# USB1_VBP2AHB_WRAP_CONTROLLER_VBP_USB3_CORE_GBL register map
Vendor: Texas Instruments
Registers are 32-bit, read-only, reset 0x0 unless marked. A register's access mark holds for its fields unless they carry their own. Offsets are as the file gives them; [hi:lo] are bit positions; lines under a group give offsets from that group; {n}, {i} and the like mark numbered series; <NAME> marks a mode.

## USB1_VBP2AHB_WRAP_CONTROLLER_VBP_USB3_CORE_GBL (part 3 of 3)
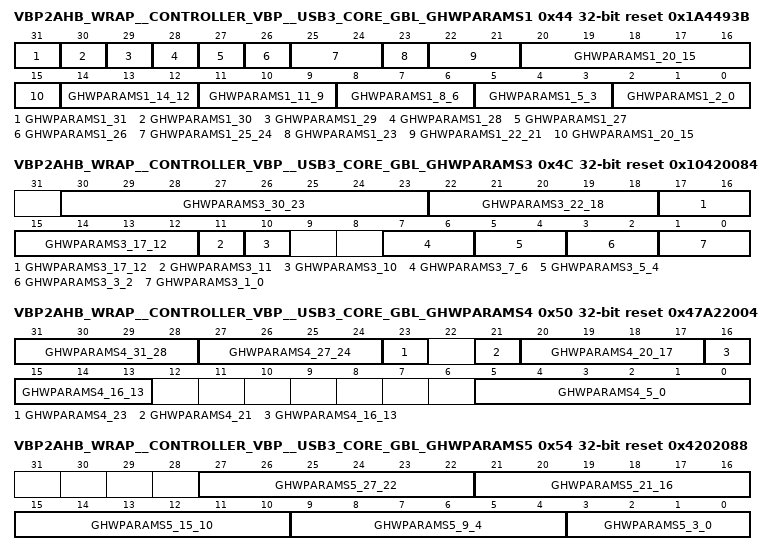
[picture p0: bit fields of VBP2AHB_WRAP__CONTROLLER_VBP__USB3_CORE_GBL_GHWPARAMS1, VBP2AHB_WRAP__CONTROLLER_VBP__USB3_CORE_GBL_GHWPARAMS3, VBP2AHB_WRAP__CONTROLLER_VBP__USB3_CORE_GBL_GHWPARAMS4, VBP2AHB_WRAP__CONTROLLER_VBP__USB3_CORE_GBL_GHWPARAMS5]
0x44 VBP2AHB_WRAP__CONTROLLER_VBP__USB3_CORE_GBL_GHWPARAMS1 reset 0x1A4493B — Global Hardware Parameters Register 1 This register contains the hardware configuration options that you can select in the coreConsultant GUI. For a description of each parameter, refer to the Parameter Descriptions chapter in the Databook. This information is also available in coreConsultant by right-clicking the parameter label and selecting What's This or by clicking the Help tab. Note: Some of the global hardware parameters are not currently modifiable in coreConsultant. These settings are in the <workspace>/src/DWC_usb3_params.v file. you must not change them.
  [31] GHWPARAMS1_31 — DWC_USB3_EN_DBC
  [30] GHWPARAMS1_30 — DWC_USB3_RM_OPT_FEATURES
  [29] GHWPARAMS1_29 — Reserved1
  [28] GHWPARAMS1_28 — DWC_USB3_RAM_BUS_CLKS_SYNC
  [27] GHWPARAMS1_27 — DWC_USB3_MAC_RAM_CLKS_SYNC
  [26] GHWPARAMS1_26 — DWC_USB3_MAC_PHY_CLKS_SYNC
  [25:24] GHWPARAMS1_25_24 — DWC_USB3_EN_PWROPT
  [23] GHWPARAMS1_23 — DWC_USB3_SPRAM_TYP
  [22:21] GHWPARAMS1_22_21 — DWC_USB3_NUM_RAMS
  [20:15] GHWPARAMS1_20_15 — DWC_USB3_DEVICE_NUM_INT For details on DWC_USB3_DEVICE_NUM_INT, refer to <workspace>/src/DWC_usb3_params.v file.
  [14:12] GHWPARAMS1_14_12 — DWC_USB3_ASPACEWIDTH
  [11:9] GHWPARAMS1_11_9 — DWC_USB3_REQINFOWIDTH
  [8:6] GHWPARAMS1_8_6 — DWC_USB3_DATAINFOWIDTH
  [5:3] GHWPARAMS1_5_3 — DWC_USB3_BURSTWIDTH-1
  [2:0] GHWPARAMS1_2_0 — DWC_USB3_IDWIDTH-1
0x48 VBP2AHB_WRAP__CONTROLLER_VBP__USB3_CORE_GBL_GHWPARAMS2 — Global Hardware Parameters Register 2 This register contains the hardware configuration options that you can select in the coreConsultant GUI. For a description of each parameter, refer to the Parameter Descriptions chapter in the Databook. This information is also available in coreConsultant by right-clicking the parameter label and selecting What's This or by clicking the Help tab. Note: Some of the global hardware parameters are not currently modifiable in coreConsultant. These settings are in the <workspace>/src/DWC_usb3_params.v file. you must not change them.
  [31:0] GHWPARAMS2_31_0 — DWC_USB3_USERID
0x4C VBP2AHB_WRAP__CONTROLLER_VBP__USB3_CORE_GBL_GHWPARAMS3 reset 0x10420084 — Global Hardware Parameters Register 3 This register contains the hardware configuration options that you can select in the coreConsultant GUI. For a description of each parameter, refer to the Parameter Descriptions chapter in the Databook. This information is also available in coreConsultant by right-clicking the parameter label and selecting What's This or by clicking the Help tab. Note: Some of the global hardware parameters are not currently modifiable in coreConsultant. These settings are in the <workspace>/src/DWC_usb3_params.v file. you must not change them.
  [30:23] GHWPARAMS3_30_23 — DWC_USB3_CACHE_TOTAL_XFER_RESOURCES
  [22:18] GHWPARAMS3_22_18 — DWC_USB3_NUM_IN_EPS
  [17:12] GHWPARAMS3_17_12 — DWC_USB3_NUM_EPS
  [11] GHWPARAMS3_11 — DWC_USB3_ULPI_CARKIT
  [10] GHWPARAMS3_10 — DWC_USB3_VENDOR_CTL_INTERFACE
  [7:6] GHWPARAMS3_7_6 — DWC_USB3_HSPHY_DWIDTH
  [5:4] GHWPARAMS3_5_4 — DWC_USB3_FSPHY_INTERFACE
  [3:2] GHWPARAMS3_3_2 — DWC_USB3_HSPHY_INTERFACE
  [1:0] GHWPARAMS3_1_0 — DWC_USB3_SSPHY_INTERFACE
0x50 VBP2AHB_WRAP__CONTROLLER_VBP__USB3_CORE_GBL_GHWPARAMS4 reset 0x47A22004 — Global Hardware Parameters Register 4 This register contains the hardware configuration options that you can select in the coreConsultant GUI. For a description of each parameter, refer to the Parameter Descriptions chapter in the Databook. This information is also available in coreConsultant by right-clicking the parameter label and selecting What's This or by clicking the Help tab. Note: Some of the global hardware parameters are not currently modifiable in coreConsultant. These settings are in the <workspace>/src/DWC_usb3_params.v file. you must not change them.
  [31:28] GHWPARAMS4_31_28 — DWC_USB3_BMU_LSP_DEPTH
  [27:24] GHWPARAMS4_27_24 — DWC_USB3_BMU_PTL_DEPTH-1
  [23] GHWPARAMS4_23 — DWC_USB3_EN_ISOC_SUPT
  [21] GHWPARAMS4_21 — DWC_USB3_EXT_BUFF_CONTROL
  [20:17] GHWPARAMS4_20_17 — DWC_USB3_NUM_SS_USB_INSTANCES
  [16:13] GHWPARAMS4_16_13 — DWC_USB3_HIBER_SCRATCHBUFS Number of external scratchpad buffers the controller requires to save its internal state in the device mode. Each buffer is assumed to be 4KB. The scratchpad buffer array must have this many buffer pointers.
  [5:0] GHWPARAMS4_5_0 — DWC_USB3_CACHE_TRBS_PER_TRANSFER
0x54 VBP2AHB_WRAP__CONTROLLER_VBP__USB3_CORE_GBL_GHWPARAMS5 reset 0x4202088 — Global Hardware Parameters Register 5 This register contains the hardware configuration options that you can select in the coreConsultant GUI. For a description of each parameter, refer to the Parameter Descriptions chapter in the Databook. This information is also available in coreConsultant by right-clicking the parameter label and selecting What's This or by clicking the Help tab. Note: Some of the global hardware parameters are not currently modifiable in coreConsultant. These settings are in the <workspace>/src/DWC_usb3_params.v file. you must not change them.
  [27:22] GHWPARAMS5_27_22 — DWC_USB3_DFQ_FIFO_DEPTH
  [21:16] GHWPARAMS5_21_16 — DWC_USB3_DWQ_FIFO_DEPTH
  [15:10] GHWPARAMS5_15_10 — DWC_USB3_TXQ_FIFO_DEPTH
  [9:4] GHWPARAMS5_9_4 — DWC_USB3_RXQ_FIFO_DEPTH
  [3:0] GHWPARAMS5_3_0 — DWC_USB3_BMU_BUSGM_DEPTH
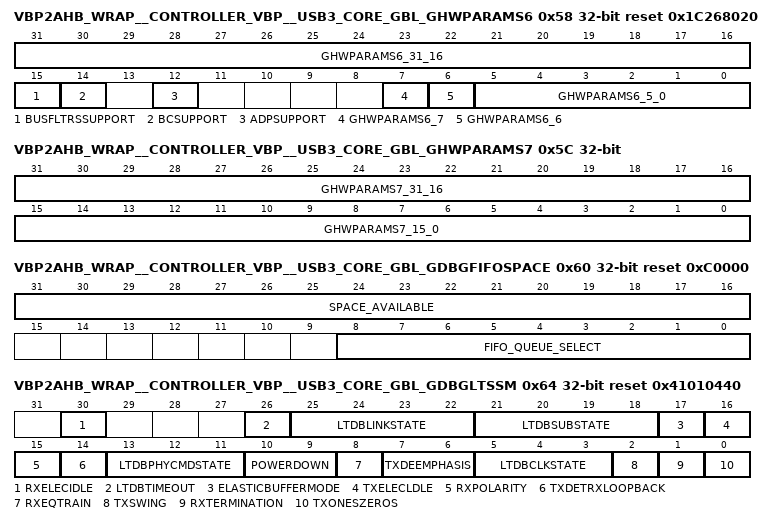
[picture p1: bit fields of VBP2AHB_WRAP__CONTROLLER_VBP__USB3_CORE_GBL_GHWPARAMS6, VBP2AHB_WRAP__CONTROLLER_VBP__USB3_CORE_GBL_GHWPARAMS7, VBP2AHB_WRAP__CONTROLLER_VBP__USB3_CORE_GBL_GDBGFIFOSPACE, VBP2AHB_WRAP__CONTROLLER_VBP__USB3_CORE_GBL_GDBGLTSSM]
0x58 VBP2AHB_WRAP__CONTROLLER_VBP__USB3_CORE_GBL_GHWPARAMS6 reset 0x1C268020 — Global Hardware Parameters Register 6 This register contains the hardware configuration options that you can select in the coreConsultant GUI. For a description of each parameter, refer to the Parameter Descriptions chapter in the Databook. This information is also available in coreConsultant by right-clicking the parameter label and selecting What's This or by clicking the Help tab. Note: Some of the global hardware parameters are not currently modifiable in coreConsultant. These settings are in the <workspace>/src/DWC_usb3_params.v file. you must not change them.
  [31:16] GHWPARAMS6_31_16 — DWC_USB3_RAM0_DEPTH
  [15] BUSFLTRSSUPPORT — DWC_USB3_EN_BUS_FILTERS
  [14] BCSUPPORT — DWC_USB3_EN_BC
  [12] ADPSUPPORT — DWC_USB3_EN_ADP
  [7] GHWPARAMS6_7 — DWC_USB3_EN_FPGA
  [6] GHWPARAMS6_6 — DWC_USB3_EN_DBG_PORTS
  [5:0] GHWPARAMS6_5_0 — DWC_USB3_PSQ_FIFO_DEPTH
0x5C VBP2AHB_WRAP__CONTROLLER_VBP__USB3_CORE_GBL_GHWPARAMS7 — Global Hardware Parameters Register 7 This register contains the hardware configuration options that you can select in the coreConsultant GUI. For a description of each parameter, refer to the Parameter Descriptions chapter in the Databook. This information is also available in coreConsultant by right-clicking the parameter label and selecting What's This or by clicking the Help tab. Note: Some of the global hardware parameters are not currently modifiable in coreConsultant. These settings are in the <workspace>/src/DWC_usb3_params.v file. you must not change them.
  [31:16] GHWPARAMS7_31_16 — DWC_USB3_RAM2_DEPTH
  [15:0] GHWPARAMS7_15_0 — DWC_USB3_RAM1_DEPTH
0x60 VBP2AHB_WRAP__CONTROLLER_VBP__USB3_CORE_GBL_GDBGFIFOSPACE access per field reset 0xC0000 — Global Debug Queue/FIFO Space Available Register Bit Bash test should not be done on this debug register.
  [31:16] SPACE_AVAILABLE ro
  [8:0] FIFO_QUEUE_SELECT rw — FIFO/Queue Select [or] Port-Select - FIFO/Queue Select[8:5] indicates the FIFO/Queue Type - FIFO/Queue Select[4:0] indicates the FIFO/Queue Number For example, 9'b0_0010_0001 refers to RxFIFO_1 and 9'b0_0101_1110 refers to TxReqQ_30. - 9'b0_0001_1111 to 9'b0_0000_0000: TxFIFO_31 to TxFIFO_0 - 9'b0_0011_1111 to 9'b0_0010_0000: RxFIFO_31 to RxFIFO_0 - 9'b0_0101_1111 to 9'b0_0100_0000: TxReqQ_31 to TxReqQ_0 - 9'b0_0111_1111 to 9'b0_0110_0000: RxReqQ_31 to RxReqQ_0 - 9'b0_1001_1111 to 9'b0_1000_0000: RxInfoQ_31 to RxInfoQ_0 - 9'b0_1010_0000: DescFetchQ_0 [for backwards compatibility] - 9'b0_1010_0001: EventQ_0 [for backwards compatibility] - 9'b0_1010_0010: ProtocolStatusQ_0 - 9'b0_1101_1111 to 9'b0_1110_0000: DescFetchQ_31 to DescFetchQ_0 - 9'b0_1111_1111 to 9'b0_1110_0000: WriteBack/EventQ_31 to WriteBack/EventQ_0 - 9'b1_0000_0111 to 9'b1_0000_0000: AuxEventQ_7 to AuxEventQ_0 [if EN_SEPARATE_DESC_QUEUES=1] Port-Select[3:0] selects the port-number when accessing GDBGLTSSM register.
0x64 VBP2AHB_WRAP__CONTROLLER_VBP__USB3_CORE_GBL_GDBGLTSSM reset 0x41010440 — Global Debug LTSSM Register In multi-port host configuration, the port-number is defined by Port-Select[3:0] field in the GDBGFIFOSPACE register. Note: - GDBGLTSSM register is not applicable for USB 2.0-only mode. - Bit Bash test should not be done on this debug register.
  [30] RXELECIDLE — RxElecidle For description of RxElecIdle, see table 5-4, Status Interface Signals of the PIPE3 Specification.
  [26] LTDBTIMEOUT — LTDB Timeout [LTDBTimeout]
  [25:22] LTDBLINKSTATE — LTDB Link State [LTDBLinkState]
  [21:18] LTDBSUBSTATE — LTDB Sub-State [LTDBSubState]
  [17] ELASTICBUFFERMODE — Elastic Buffer Mode [ElasticBufferMode] For field definition, refer to Table 5-3 of the PIPE3 specification.
  [16] TXELECLDLE — Tx Elec Idle [TxElecIdle] For field definition, refer to Table 5-3 of the PIPE3 specification.
  [15] RXPOLARITY — Rx Polarity [RxPolarity] For field definition, refer to Table 5-3 of the PIPE3 specification.
  [14] TXDETRXLOOPBACK — Tx Detect Rx/Loopback [TxDetRxLoopback] For field definition, refer to Table 5-3 of the PIPE3 specification.
  [13:11] LTDBPHYCMDSTATE — LTSSM PHY command State [LTDBPhyCmdState] - 000: PHY_IDLE [PHY command state is in IDLE. No PHY request pending] - 001: PHY_DET [Request to start Receiver detection] - 010: PHY_DET_3 [Wait for Phy_Status [Receiver detection]] - 011: PHY_PWR_DLY [Delay Pipe3_PowerDown P0 -> P1/P2/P3 request] - 100: PHY_PWR_A [Delay for internal logic] - 101: PHY_PWR_B [Wait for Phy_Status[Power state change request]]
  [10:9] POWERDOWN — POWERDOWN [PowerDown] For field definition, refer to Table 5-3 of the PIPE3 specification.
  [8] RXEQTRAIN — RxEq Train For field definition, refer to Table 5-3 of the PIPE3 specification.
  [7:6] TXDEEMPHASIS — TXDEEMPHASIS [TxDeemphasis] For field definition, refer to Table 5-3 of the PIPE3 specification.
  [5:3] LTDBCLKSTATE — LTSSM Clock State [LTDBClkState] In multi-port host configuration, the port number is defined by Port-Select[3:0] field in the GDBGFIFOSPACE register. Note: GDBGLTSSM register is not applicable for USB 2.0-only mode. - 000: CLK_NORM [PHY is in non-P3 state and PCLK is running] - 001: CLK_TO_P3 [P3 entry request to PHY]. - 010: CLK_WAIT1 [Wait for Phy_Status [P3 request]]. - 011: CLK_P3 [PHY is in P3 and PCLK is not running]. - 100: CLK_TO_P0 [P3 exit request to PHY]. - 101: CLK_WAIT2 [Wait for Phy_Status [P3 exit request]]
  [2] TXSWING — Tx Swing [TxSwing] For field definition, refer to Table 5-3 of the PIPE3 specification.
  [1] RXTERMINATION — Rx Termination [RxTermination] For details on DWC_USB3_PIPE_RXTERM_RESET_VAL, refer to <workspace>/src/DWC_usb3_params.v
  [0] TXONESZEROS — Tx Ones/Zeros [TxOnesZeros] For field definition, refer to Table 5-3 of the PIPE3 specification.
0x68 VBP2AHB_WRAP__CONTROLLER_VBP__USB3_CORE_GBL_GDBGLNMCC — Global Debug LNMCC Register Bit Bash test should not be done on this debug register.
  [8:0] LNMCC_BERC — This field indicates the bit error rate information for the port selected in the GDBGFIFOSPACE.PortSelect field. This field is for debug purposes only.
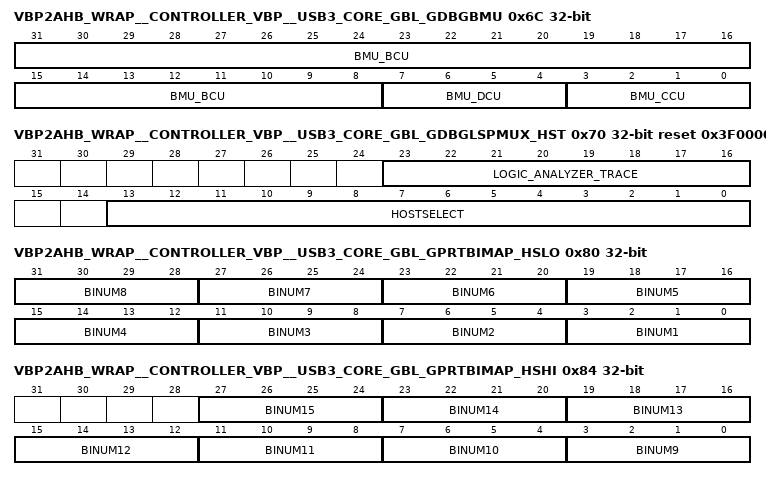
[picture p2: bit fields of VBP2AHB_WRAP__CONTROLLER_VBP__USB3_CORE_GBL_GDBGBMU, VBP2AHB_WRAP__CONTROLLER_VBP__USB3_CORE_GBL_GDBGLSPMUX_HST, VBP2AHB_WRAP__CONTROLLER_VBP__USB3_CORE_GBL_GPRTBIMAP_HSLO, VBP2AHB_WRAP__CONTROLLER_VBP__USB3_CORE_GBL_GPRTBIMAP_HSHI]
0x6C VBP2AHB_WRAP__CONTROLLER_VBP__USB3_CORE_GBL_GDBGBMU — Global Debug BMU Register Bit Bash test should not be done on this debug register.
  [31:8] BMU_BCU — BMU_BCU Debug information
  [7:4] BMU_DCU — BMU_DCU Debug information
  [3:0] BMU_CCU — BMU_CCU Debug information
0x70 VBP2AHB_WRAP__CONTROLLER_VBP__USB3_CORE_GBL_GDBGLSPMUX_HST rw reset 0x3F0000 — Global Debug LSP MUX Register - Host This register is for internal use only. If DWC_USB3_PRESERVE_LOGIC_ANALYZER_SELECT is enabled during controller configuration, then the default values readout is X (Undefined). Bit Bash test should not be done on this debug register.
  [23:16] LOGIC_ANALYZER_TRACE — logic_analyzer_trace Port MUX Select Currently only bits[21:16] are used. For details on how the mux controls the debug traces, refer to the assign logic_analyzer_trace = code section in the DWC_usb3.v file. A value of 6'h3F drives 0s on the logic_analyzer_trace signal. If you plan to OR [instead using a mux] this signal with other trace signals in your system to generate a common trace signal, you can use this feature.
  [13:0] HOSTSELECT — Device LSP Select Selects the LSP debug information presented in the GDBGLSP register in host mode.
0x74 VBP2AHB_WRAP__CONTROLLER_VBP__USB3_CORE_GBL_GDBGLSP — Global Debug LSP Register This register is for internal debug purposes only. This register is for internal use only. If DWC_USB3_PRESERVE_LOGIC_ANALYZER_SELECT is enabled during controller configuration, then the default values readout is X (Undefined). Bit Bash test should not be done on this debug register.
  [31:0] LSPDEBUG — LSP Debug Information
0x78 VBP2AHB_WRAP__CONTROLLER_VBP__USB3_CORE_GBL_GDBGEPINFO0 — Global Debug Endpoint Information Register 0 This register is for internal use only. If DWC_USB3_PRESERVE_LOGIC_ANALYZER_SELECT is enabled during controller configuration, then the default values readout is X (Undefined). Bit Bash test should not be done on this debug register.
  [31:0] EPDEBUG — Endpoint Debug Information, bits[31:0]
0x7C VBP2AHB_WRAP__CONTROLLER_VBP__USB3_CORE_GBL_GDBGEPINFO1 reset 0x800000 — Global Debug Endpoint Information Register 1 This register is for internal use only. If DWC_USB3_PRESERVE_LOGIC_ANALYZER_SELECT is enabled during controller configuration, then the default values readout is X (Undefined). Bit Bash test should not be done on this debug register.
  [31:0] EPDEBUG — Endpoint Debug Information, bits[63:32]
0x80 VBP2AHB_WRAP__CONTROLLER_VBP__USB3_CORE_GBL_GPRTBIMAP_HSLO access per field — Global High-Speed Port to Bus Instance Mapping Register - Low This is an alternate register for the GPRTBIMAP_HS register. - Register fields are read-write with respect to number of port instantiated. writeAsRead constraint is added to limit side effects for unused fields. Note: For reset values, refer to the corresponding values in the GPRTBIMAP_HS register.
  [31:28] BINUM8 ro — BINUM8: HS USB Instance Number for Port 8. Application-programmable ID field.
  [27:24] BINUM7 ro — BINUM7: HS USB Instance Number for Port 7. Application-programmable ID field.
  [23:20] BINUM6 ro — BINUM6 USB Instance Number for Port 6. Application-programmable ID field.
  [4n-1:4n-4] BINUM{n} ro (n=2..5) — BINUM{n}: HS USB Instance Number for Port {n}. Application-programmable ID field.
  [3:0] BINUM1 rw — BINUM1: HS USB Instance Number for Port 1. Application-programmable ID field.
0x84 VBP2AHB_WRAP__CONTROLLER_VBP__USB3_CORE_GBL_GPRTBIMAP_HSHI — Global High-Speed Port to Bus Instance Mapping Register - High This is an alternate register for the GPRTBIMAP_HS register. - Register fields are read-write with respect to number of port instantiated. writeAsRead constraint is added to limit side effects for unused fields. Note: For reset values, refer to the corresponding values in the GPRTBIMAP register.
  [27:24] BINUM15 — BINUM15: HS USB Instance Number for Port 15. Application-programmable ID field.
  [23:20] BINUM14 — BINUM14: HS USB Instance Number for Port 14. Application-programmable ID field.
  [19:16] BINUM13 — BINUM13: HS USB Instance Number for Port 13. Application-programmable ID field.
  [15:12] BINUM12 — BINUM12: HS USB Instance Number for Port 12. SApplication-programmable ID field.
  [11:8] BINUM11 — BINUM11: HS USB Instance Number for 11. Application-programmable ID field.
  [7:4] BINUM10 — BINUM10: HS USB Instance Number for Port 10. Application-programmable ID field.
  [3:0] BINUM9 — BINUM9: HS USB Instance Number for Port 9. Application-programmable ID field.
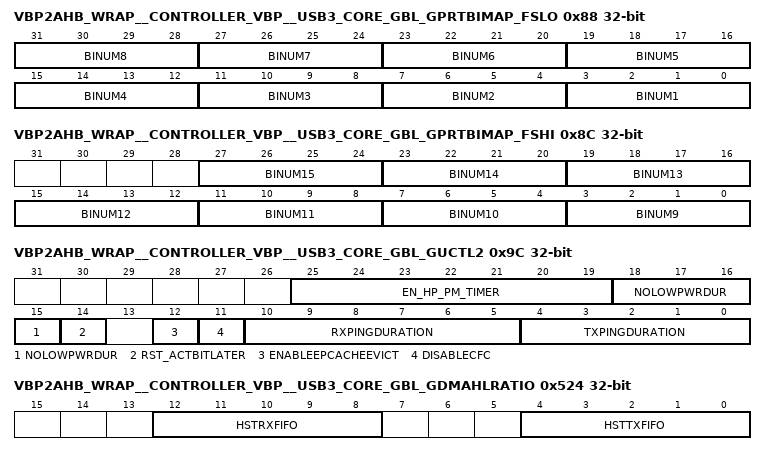
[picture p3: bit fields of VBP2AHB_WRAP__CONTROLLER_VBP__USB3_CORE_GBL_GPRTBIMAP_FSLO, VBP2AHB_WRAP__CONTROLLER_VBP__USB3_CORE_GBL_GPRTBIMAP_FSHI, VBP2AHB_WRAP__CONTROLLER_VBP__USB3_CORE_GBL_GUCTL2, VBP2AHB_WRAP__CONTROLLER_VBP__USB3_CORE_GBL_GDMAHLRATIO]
0x88 VBP2AHB_WRAP__CONTROLLER_VBP__USB3_CORE_GBL_GPRTBIMAP_FSLO access per field — Global Full-Speed Port to Bus Instance Mapping Register - Low This is an alternate register for the GPRTBIMAP_FS register. - Register fields are read-write with respect to number of port instantiated. writeAsRead constraint is added to limit side effects for unused fields. Note: For reset values, refer to the corresponding values in the GPRTBIMAP_FS register.
  [4n-1:4n-4] BINUM{n} ro (n=2..8) — BINUM{n}: FS USB Instance Number for Port {n}. Application-programmable ID field.
  [3:0] BINUM1 rw — BINUM1: FS USB Instance Number for Port 1. Application-programmable ID field.
0x8C VBP2AHB_WRAP__CONTROLLER_VBP__USB3_CORE_GBL_GPRTBIMAP_FSHI — Global Full-Speed Port to Bus Instance Mapping Register - High This is an alternate register for the GPRTBIMAP_FS register. - Register fields are read-write with respect to number of port instantiated. writeAsRead constraint is added to limit side effects for unused fields. Note: For reset values, refer to the corresponding values in the GPRTBIMAP_FS register.
  [4n-33:4n-36] BINUM{n} (n=10..15) — BINUM{n}: FS USB Instance Number for Port {n}. Application-programmable ID field
  [3:0] BINUM9 — BINUM9: FS USB Instance Number for Port 9. Application-programmable ID field.
0x94 VBP2AHB_WRAP__CONTROLLER_VBP__USB3_CORE_GBL_Reserved_94 access not given — Future Reserved Register at offset 0x94
  [31:0] RESERVED — Future use Register field (access N/A)
0x98 VBP2AHB_WRAP__CONTROLLER_VBP__USB3_CORE_GBL_Reserved_98 access not given — Future Reserved Register at offset 0x98
  [31:0] RESERVED — Field for future use (access N/A)
0x9C VBP2AHB_WRAP__CONTROLLER_VBP__USB3_CORE_GBL_GUCTL2 access not given — Global User Control Register 2: This register provides a few options for the software to control the controller behavior in the Host and device mode. Most of the options are used to improve inter-operability with different hosts and devices.
  [25:19] EN_HP_PM_TIMER rw — This register field is used to set new HP and PM timers. - To enable PM timer, set GUCTL2[19] bit as 1. - To enable HP timer, set GUCTL2[20] bit as 1. Default value of HP timer is 4us when HP PM timer is not enabled. when new HP timer is enabled default value is 12us. Use GUCTL2[25:21] to specify HP timer value in microseconds.
  [18:15] NOLOWPWRDUR rw — No Low Power Duration [NOLOWPWRDUR] This bit is applicable for device mode only and is ignored in host mode. After starting a transfer on a SS ISOC endpoint, the application must program these bits to prevent the device to lose frame synchronization over a period of time. Based on this count-down counter, the device will wake itself from U1/U2 low power states. After entering to U0 state and receiving two ITPs [which will sync-up the host and the device], U1/U2 low power entry is allowed. Each count represents the duration in terms of milliseconds. For example, a value of 3 represents 3ms. Note: - To disable this feature, set this field to 4'b0. - These bits are applicable only in device mode and ignored in host mode. - Some xHCI hosts do not send ITPs when performing ISOC transfers when the link enters U1/U2 low power states. This causes the device to lose frame synchronization over a period of time resulting in ISOC packets being dropped.
  [14] RST_ACTBITLATER rw — Enable clearing of the command active bit for the ENDXFER command after the command execution is completed. This bit is valid in device mode only.
  [12] ENABLEEPCACHEEVICT rw — Enable Evicting Endpoint cache after Flow Control for bulk endpoints. In 3.00a release, a performance enhancement was done to keep the non-stream capable bulk IN endpoint in cache after flow control. Setting this bit will disable this enhancement. This should be set only for debug purpose.
  [11] DISABLECFC rw — Disable xHCI Errata Feature Contiguous Frame ID Capability This field controls the xHCI Errata feature Contiguous FrameID capability. When set, the xHCI HCCPARAMS1 bit 11 will be set to 0 indicating that CFC is not supported. Disable this feature only if your application cannot tolerate Misssed Service Error events for Isoc transfers, and your system latencies are large to cause Missed Service errors even if the software is following the Isochronous Thresholding rules.
  [10:5] RXPINGDURATION rw — Recieve Ping Maximum Duration This field is relevant to Host mode and controls the maximum duration of received LFPS to be treated as a Ping LFPS. The Max duration of the Ping LFPS is controlled by programming this value and is in terms of 8 ns granularity. Eg: A value of 32 indicates 256 ns.
  [4:0] TXPINGDURATION rw — Transmit Ping Maximum Duration This field is relevant to Device mode and controls the maximum duration for which the controller should instruct the PHY to transmit a Ping LFPS. The duration of the Ping LFPS is controlled by programming this value and is in terms of 8 ns granularity. Eg: A value of 13 indicates 104 ns.
0x500 VBP2AHB_WRAP__CONTROLLER_VBP__USB3_CORE_GBL_GHWPARAMS8 reset 0x660 — Global Hardware Parameters Register 8 This register contains the hardware configuration options that you can select in the coreConsultant GUI. For a description of each parameter, refer to the Parameter Descriptions chapter in the Databook. This information is also available in coreConsultant by right-clicking the parameter label and selecting What's This or by clicking the Help tab. Note: Some of the global hardware parameters are not currently modifiable in coreConsultant. These settings are in the <workspace>/src/DWC_usb3_params.v file. you must not change them.
  [31:0] GHWPARAMS8_32_0 — DWC_USB3_DCACHE_DEPTH_INFO
0x50C VBP2AHB_WRAP__CONTROLLER_VBP__USB3_CORE_GBL_GUCTL3 rw — Global User Control Register 3 This register provides a few options for the software to control the controller behavior in the Host mode. Most of the options are used to improve host inter-operability with different devices.
  [16] SCH_PING_EARLY — Enable SuperSpeed Ping Transaction Packet scheduling early in the microframe. This bit is valid in Host mode only.
0x510 VBP2AHB_WRAP__CONTROLLER_VBP__USB3_CORE_GBL_GTXFIFOPRIDEV rw — Global Device TX FIFO DMA Priority Register This register specifies the relative DMA priority level among the Device TXFIFOs (one per IN endpoint). Each register bit[n] controls the priority (1: high, 0: low) of each TXFIFO[n]. When multiple TXFIFOs compete for DMA service at a given time (that is, multiple TXQs contain TX DMA requests and their corresponding TXFIFOs have space available), the TX DMA arbiter grants access on a packet-basis in the following manner: - 1. High-priority TXFIFOs are granted access using round-robin arbitration - 2. Low-priority TXFIFOs are granted access using round-robin arbitration only after the high-priority TXFIFOs have no further processing to do (that is, either the TXQs are empty or the corresponding TXFIFOs are full). For scatter-gather packets, the arbiter grants successive DMA requests to the same FIFO until the entire packet is completed. When configuring periodic IN endpoints, software must set register bit[n]=1, where n is the TXFIFO assignment. This ensures that the DMA for isochronous or interrupt IN endpoints are prioritized over bulk or control IN endpoints. This register is present only when the controller is configured to operate in the device mode (includes DRD mode). The register size corresponds to the number of Device IN endpoints. Note - Since the device mode uses only one RXFIFO, there is no Device RXFIFO DMA Priority Register.
  [15:0] GTXFIFOPRIDEV — Device TxFIFO priority
0x518 VBP2AHB_WRAP__CONTROLLER_VBP__USB3_CORE_GBL_GTXFIFOPRIHST rw — Global Host TX FIFO DMA Priority Register This register specifies the relative DMA priority level among the Host TXFIFOs (one per USB bus instance) within the associated speed group (SS or HS/FSLS). Each register bit[n] controls the priority (1: high, 0: low) of TXFIFO[n] within a speed group. When multiple TXFIFOs compete for DMA service at a given time (i.e., multiple TXQs contain TX DMA requests and their corresponding TXFIFOs have space available), the TX DMA arbiter grants access on a packet-basis in the following manner: - 1. Among the FIFOs in the same speed group (SS or HS/FSLS): a. High-priority TXFIFOs are granted access using round-robin arbitration b. Low-priority TXFIFOs are granted access using round-robin arbitration only after the high-priority TXFIFOs have no further processing to do (that is, either the TXQs are empty or the corresponding TXFIFOs are full). - 2. The TX DMA arbiter prioritizes the SS speed group or HS/FSLS speed group according to the ratio programmed in the GDMAHLRATIO register. For scatter-gather packets, the arbiter grants successive DMA requests to the same FIFO until the entire packet is completed. This register is present only when the controller is configured to operate in the host mode (includes DRD mode). The register size corresponds to the number of configured USB bus instances. for example, in the default configuration, there are 3 USB bus instances (1 SS, 1 HS, and 1 FSLS).
  [2:0] GTXFIFOPRIHST — Host TxFIFO priority
0x51C VBP2AHB_WRAP__CONTROLLER_VBP__USB3_CORE_GBL_GRXFIFOPRIHST rw — Global Host RX FIFO DMA Priority Register This register specifies the relative DMA priority level among the Host RXFIFOs (one per USB bus instance) within the associated speed group (SS or HS/FSLS). Each register bit[n] controls the priority (1: high, 0: low) of RXFIFO[n] within a speed group. When multiple RXFIFOs compete for DMA service at a given time (i.e., multiple RXQs contain RX DMA requests and their corresponding RXFIFOs have data available), the RX DMA arbiter grants access on a packet-basis in the following manner: - 1. Among the FIFOs in the same speed group (SS or HS/FSLS): a. High-priority RXFIFOs are granted access using round-robin arbitration b. Low-priority RXFIFOs are granted access using round-robin arbitration only after high-priority RXFIFOs have no further processing to do (that is, either the RXQs are empty or the corresponding RXFIFOs do not have the required data). - 2. The RX DMA arbiter prioritizes the SS speed group or HS/FSLS speed group according to the ratio programmed in the GDMAHLRATIO register. For scatter-gather packets, the arbiter grants successive DMA requests to the same FIFO until the entire packet is completed. This register is present only when the controller is configured to operate in the host mode (includes DRD mode). The register size corresponds to the number of configured USB bus instances. for example, in the default configuration, there are 3 USB bus instances (1 SS, 1 HS, and 1 FSLS).
  [2:0] GRXFIFOPRIHST — Host RxFIFO priority
0x524 VBP2AHB_WRAP__CONTROLLER_VBP__USB3_CORE_GBL_GDMAHLRATIO rw — Global Host FIFO DMA High-Low Priority Ratio Register This register specifies the relative priority of the SS FIFOs with respect to the HS/FSLS FIFOs. The DMA arbiter prioritizes the HS/FSLS round-robin arbiter group every DMA High-Low Priority Ratio grants as indicated in the register separately for TX and RX. To illustrate, consider that all FIFOs are requesting access simultaneously, and the ratio is 4. SS gets priority for 4 packets, HS/FSLS gets priority for 1 packet, SS gets priority for 4 packets, HS/FSLS gets priority for 1 packet, and so on. If FIFOs from both speed groups are not requesting access simultaneously then, - if SS got grants 4 out of the last 4 times, then HS/FSLS get the priority on any future request. - if HS/FSLS got the grant last time, SS gets the priority on the next request. - if there is a valid request on either SS or HS/FSLS, a grant is always awarded. there is no idle. This register is present if the controller is configured to operate in host mode (includes DRD).
  [12:8] HSTRXFIFO — Host RXFIFO DMA High-Low Priority
  [4:0] HSTTXFIFO — Host TXFIFO DMA High-Low Priority
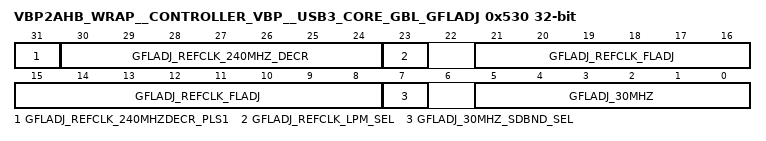
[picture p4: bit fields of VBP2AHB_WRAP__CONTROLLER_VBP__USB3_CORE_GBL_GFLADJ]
0x530 VBP2AHB_WRAP__CONTROLLER_VBP__USB3_CORE_GBL_GFLADJ access not given — Global Frame Length Adjustment Register This register provides options for the software to control the controller behavior with respect to SOF (Start of Frame) and ITP (Isochronous Timestamp Packet) timers and frame timer functionality. It provides an option to override the fladj_30mhz_reg sideband signal. In addition, it enables running SOF or ITP frame timer counters completely from the ref_clk. This facilitates hardware LPM in host mode with the SOF or ITP counters being run from the ref_clk signal.
  [31] GFLADJ_REFCLK_240MHZDECR_PLS1 rw — GFLADJ_REFCLK_240MHZDECR_PLS1 This field indicates that the decrement value that the controller applies for each ref_clk must be GFLADJ_REFCLK_240MHZ_DECR and GFLADJ_REFCLK_240MHZ_DECR +1 alternatively on each ref_clk. Set this bit to a '1' only if GFLADJ_REFCLK_LPM_SEL is set to '1' and the fractional component of 240/ref_frequency is greater than or equal to 0.5. Examples: If the ref_clk is 19.2 MHz then - GUCTL.REF_CLK_PERIOD = 52 - GFLADJ.GFLADJ_REFCLK_240MHZ_DECR = [240/19.2] = 12.5 - GFLADJ.GFLADJ_REFCLK_240MHZDECR_PLS1 = 1 If the ref_clk is 24 MHz then - GUCTL.REF_CLK_PERIOD = 41 - GFLADJ.GFLADJ_REFCLK_240MHZ_DECR = [240/24] = 10 - GFLADJ.GFLADJ_REFCLK_240MHZDECR_PLS1 = 0
  [30:24] GFLADJ_REFCLK_240MHZ_DECR rw — This field indicates the decrement value that the controller applies for each ref_clk in order to derive a frame timer in terms of a 240-MHz clock. This field must be programmed to a non-zero value only if GFLADJ_REFCLK_LPM_SEL is set to '1'. The value is derived as follows: GFLADJ_REFCLK_240MHZ_DECR = 240/ref_clk_frequency Examples: If the ref_clk is 24 MHz then - GUCTL.REF_CLK_PERIOD = 41 - GFLADJ.GFLADJ_REFCLK_240MHZ_DECR = 240/24 = 10 If the ref_clk is 48 MHz then - GUCTL.REF_CLK_PERIOD = 20 - GFLADJ.GFLADJ_REFCLK_240MHZ_DECR = 240/48 = 5 If the ref_clk is 17 MHz then - GUCTL.REF_CLK_PERIOD = 58 - GFLADJ.GFLADJ_REFCLK_240MHZ_DECR = 240/17 = 14
  [23] GFLADJ_REFCLK_LPM_SEL rw — This bit enables the functionality of running SOF/ITP counters on the ref_clk. This bit must not be set to '1' if GCTL.SOFITPSYNC bit is set to '1'. Similarly, if GFLADJ_REFCLK_LPM_SEL set to '1', GCTL.SOFITPSYNC must not be set to '1'. In device mode, setting this bit to '1' enables SOF tracking using ref_clk. When GFLADJ_REFCLK_LPM_SEL is set to '1' the overloading of the suspend control of the USB 2.0 first port PHY [UTMI/ULPI] with USB 3.0 port states is removed. For example, for Synopsys PHY, the COMMONONN signal can be tied to '1'. Note that the ref_clk frequencies supported in this mode are 16/17/19.2/20/24/39.7/40 MHz. The utmi_clk[0] signal of the controller must be connected to the FREECLK of the PHY. Note: If you set this bit to '1', the GUSB2PHYCFG.U2_FREECLK_EXISTS bit must be set to '0'.
  [21:8] GFLADJ_REFCLK_FLADJ rw — This field indicates the frame length adjustment to be applied when SOF/ITP counter is running on the ref_clk. This register value is used to adjust the ITP interval when GCTL[SOFITPSYNC] is set to '1'. SOF and ITP interval when GLADJ.GFLADJ_REFCLK_LPM_SEL is set to '1'. This field must be programmed to a non-zero value only if GFLADJ_REFCLK_LPM_SEL is set to '1' or GCTL.SOFITPSYNC is set to '1'. The value is derived as follows: FLADJ_REF_CLK_FLADJ=[[125000/ref_clk_period_integer]-[125000/ref_clk_period]] * ref_clk_period where - the ref_clk_period_integer is the integer value of the ref_clk period got by truncating the decimal [fractional] value that is programmed in the GUCTL.REF_CLK_PERIOD field. - the ref_clk_period is the ref_clk period including the fractional value. Examples: If the ref_clk is 24 MHz then - GUCTL.REF_CLK_PERIOD = 41 - GFLADJ.GLADJ_REFCLK_FLADJ = [[125000/41]-[125000/41.6666]]*41.6666 = 2032 [ignoring the fractional value] If the ref_clk is 48 MHz then - GUCTL.REF_CLK_PERIOD = 20 - GFLADJ.GLADJ_REFCLK_FLADJ = [[125000/20]-[125000/20.8333]]*20.8333 = 5208 [ignoring the fractional value]
  [7] GFLADJ_30MHZ_SDBND_SEL rw — GFLADJ_30MHZ_SDBND_SEL This field selects whether to use the input signal fladj_30mhz_reg or the GFLADJ.GFLADJ_30MHZ to adjust the frame length for the SOF/ITP. When this bit is set to, - 1, the controller uses the register field GFLADJ.GFLADJ_30MHZ value - 0, the controller uses the input signal fladj_30mhz_reg value
  [5:0] GFLADJ_30MHZ rw — GFLADJ_30MHZ This field indicates the value that is used for frame length adjustment instead of considering from the sideband input signal fladj_30mhz_reg. This enables post-silicon frame length adjustment in case the input signal fladj_30mhz_reg is connected to a wrong value or is not valid. For details on how to set this value, refer to section 5.2.4, Frame Length Adjustment Register [FLADJ], of the xHCI Specification.
